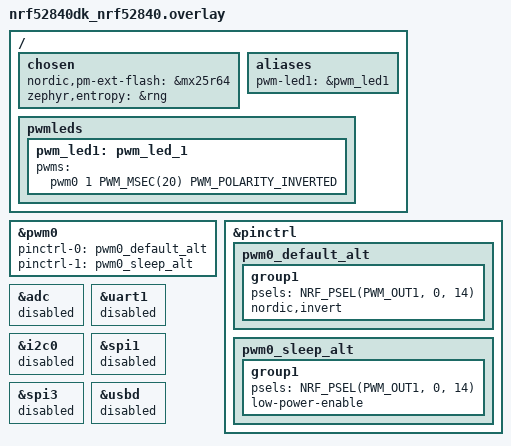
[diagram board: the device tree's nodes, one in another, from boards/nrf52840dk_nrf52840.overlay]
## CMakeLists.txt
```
#
# Copyright (c) 2021 Nordic Semiconductor ASA
#
# SPDX-License-Identifier: LicenseRef-Nordic-5-Clause
#

cmake_minimum_required(VERSION 3.20.0)

find_package(Zephyr HINTS $ENV{ZEPHYR_BASE})

project(matter-light-bulb)

# Enable GNU STD support.
include(${ZEPHYR_CONNECTEDHOMEIP_MODULE_DIR}/config/nrfconnect/app/enable-gnu-std.cmake)

# NORDIC SDK APP START

# Include all source files that are located in the Matter common directory.
include(${ZEPHYR_NRF_MODULE_DIR}/samples/matter/common/cmake/source_common.cmake)

# Include Data Model utils
include(${ZEPHYR_NRF_MODULE_DIR}/samples/matter/common/cmake/data_model.cmake)

target_include_directories(app PRIVATE
    src
    ${CONFIG_NCS_SAMPLE_MATTER_ZAP_FILES_PATH}
)

target_sources(app PRIVATE
    src/app_task.cpp
    src/main.cpp
    src/zcl_callbacks.cpp
)

ncs_configure_data_model(
    ZAP_FILE ${CMAKE_CURRENT_SOURCE_DIR}/${CONFIG_NCS_SAMPLE_MATTER_ZAP_FILES_PATH}/thread_platform.zap
)
# NORDIC SDK APP END
```

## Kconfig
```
#
# Copyright (c) 2022 Nordic Semiconductor
#
# SPDX-License-Identifier: LicenseRef-Nordic-5-Clause
#
mainmenu "Matter nRF Connect Platform"

# Sample configuration used for Thread networking
if OPENTHREAD

choice OPENTHREAD_NORDIC_LIBRARY_CONFIGURATION
	default OPENTHREAD_NORDIC_LIBRARY_MTD
endchoice

choice OPENTHREAD_DEVICE_TYPE
	default OPENTHREAD_MTD
endchoice

config CHIP_ENABLE_ICD_SUPPORT
	default y

config CHIP_ICD_LIT_SUPPORT
	default y

config CHIP_ICD_SIT_SLOW_POLL_LIMIT
	default 5000

config CHIP_ICD_REPORT_ON_ACTIVE_MODE
	default y

# Increase the supported event triggers due to the multiple alarm triggers
config NCS_SAMPLE_MATTER_TEST_EVENT_TRIGGERS_MAX
	default 12

# Reduce Thread TX output power to 0 dBm for SED device
config OPENTHREAD_DEFAULT_TX_POWER
	int
	default 0

endif # OPENTHREAD

source "${ZEPHYR_CONNECTEDHOMEIP_MODULE_DIR}/config/nrfconnect/chip-module/Kconfig.features"
source "${ZEPHYR_CONNECTEDHOMEIP_MODULE_DIR}/config/nrfconnect/chip-module/Kconfig.defaults"
source "${ZEPHYR_NRF_MODULE_DIR}/samples/matter/common/src/Kconfig"
source "Kconfig.zephyr"
```

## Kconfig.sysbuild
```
#
# Copyright (c) 2023 Nordic Semiconductor ASA
#
# SPDX-License-Identifier: LicenseRef-Nordic-5-Clause
#

config WIFI_NRF70
	default y if BOARD_NRF7002DK

#### Radio core selection
config NRF_DEFAULT_IPC_RADIO
	default y

# Enable IEEE802.15.4 serialization to network core
# This config automatically pulls in the `overlay-802154.conf` in the ipc_radio image
config NETCORE_IPC_RADIO_IEEE802154
	default y if SOC_SERIES_NRF53X && !WIFI_NRF70

# Enable Bluetooth serialization to network core
# This config automatically pulls in the `overlay-bt_hci_ipc.conf` in the ipc_radio image
config NETCORE_IPC_RADIO_BT_HCI_IPC
	default y if SOC_SERIES_NRF53X

#### Bootloader
choice BOOTLOADER
	default BOOTLOADER_MCUBOOT if !BOARD_NRF21540DK
endchoice

if BOOTLOADER_MCUBOOT

#### DFU multi-image support
config DFU_MULTI_IMAGE_PACKAGE_BUILD
	default y

config DFU_MULTI_IMAGE_PACKAGE_APP
	default y

config PM_EXTERNAL_FLASH_MCUBOOT_SECONDARY
	default y

#### DFU network core configuration
if SOC_SERIES_NRF53X

config MCUBOOT_UPDATEABLE_IMAGES
	default 2

choice MCUBOOT_MODE
	default MCUBOOT_MODE_OVERWRITE_ONLY
endchoice

choice BOOT_SIGNATURE_TYPE
	default BOOT_SIGNATURE_TYPE_RSA
endchoice

config SECURE_BOOT_NETCORE
	default y

config NETCORE_APP_UPDATE
	default y

config DFU_MULTI_IMAGE_PACKAGE_NET
	default y

endif # SOC_SERIES_NRF53X

if BOARD_NRF54L15DK

config PM_OVERRIDE_EXTERNAL_DRIVER_CHECK
	default y

endif # BOARD_NRF54L15DK

endif # BOOTLOADER_MCUBOOT

#### Enable generating factory data
config MATTER_FACTORY_DATA_GENERATE
	default y if !BOARD_NRF21540DK

source "share/sysbuild/Kconfig"
```

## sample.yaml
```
sample:
  description: Matter Platform
  name: Matter Platform
tests:
  sample.matter.platform.debug:
    sysbuild: true
    build_only: true
    extra_args:
      - platform_SNIPPET="diagnostic-logs;matter-debug"
    integration_platforms:
      - nrf52840dk/nrf52840
      - nrf5340dk/nrf5340/cpuapp
      - nrf54l15dk/nrf54l15/cpuapp
      - nrf54l15dk/nrf54l15/cpuapp/ns
    platform_allow:
      - nrf52840dk/nrf52840
      - nrf5340dk/nrf5340/cpuapp
      - nrf54l15dk/nrf54l15/cpuapp
      - nrf54l15dk/nrf54l15/cpuapp/ns
    tags:
      - sysbuild
      - ci_samples_matter
```

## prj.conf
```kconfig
#
# Copyright (c) 2022 Nordic Semiconductor ASA
#
# SPDX-License-Identifier: LicenseRef-Nordic-5-Clause
#

# Enable CHIP
CONFIG_CHIP=y
CONFIG_CHIP_PROJECT_CONFIG="src/chip_project_config.h"
# 32773 == 0x8005 (example lighting-app)
CONFIG_CHIP_DEVICE_PRODUCT_ID=32773
CONFIG_STD_CPP17=y

# Enable Matter pairing automatically on application start.
CONFIG_CHIP_ENABLE_PAIRING_AUTOSTART=y

# Enable Matter extended announcement and increase duration to 1 hour.
CONFIG_CHIP_BLE_EXT_ADVERTISING=y
CONFIG_CHIP_BLE_ADVERTISING_DURATION=60

# Add support for LEDs and buttons on Nordic development kits
CONFIG_DK_LIBRARY=y
CONFIG_PWM=y

# Bluetooth Low Energy configuration
CONFIG_BT_DEVICE_NAME="MatterPlatform"

# Other settings
CONFIG_THREAD_NAME=y
CONFIG_MPU_STACK_GUARD=y
CONFIG_RESET_ON_FATAL_ERROR=n
CONFIG_CHIP_LIB_SHELL=y
CONFIG_NCS_SAMPLE_MATTER_TEST_SHELL=y

# Reduce application size
CONFIG_USE_SEGGER_RTT=n

# Enable Factory Data feature
CONFIG_CHIP_FACTORY_DATA=y
CONFIG_CHIP_FACTORY_DATA_BUILD=y

CONFIG_CHIP_ENABLE_READ_CLIENT=y
```

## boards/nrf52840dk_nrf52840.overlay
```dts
/*
 * Copyright (c) 2021-2022 Nordic Semiconductor ASA
 *
 * SPDX-License-Identifier: LicenseRef-Nordic-5-Clause
 */

/ {
	chosen {
		nordic,pm-ext-flash = &mx25r64;
	};

	/*
	* In some default configurations within the nRF Connect SDK,
	* e.g. on nRF52840, the chosen zephyr,entropy node is &cryptocell.
	* This devicetree overlay ensures that default is overridden wherever it
	* is set, as this application uses the RNG node for entropy exclusively.
	*/

	chosen {
		zephyr,entropy = &rng;
	};

	/*
	* By default, PWM module is only configured for led0 (LED1 on the board).
	* The light bulb app, however, uses LED2 to show the state of the lighting,
	* including its brightness level.
	*/
	aliases {
		pwm-led1 = &pwm_led1;
	};

	pwmleds {
		pwm_led1: pwm_led_1 {
			pwms = <&pwm0 1 PWM_MSEC(20) PWM_POLARITY_INVERTED>;
		};
	};

};

&pwm0 {
	pinctrl-0 = <&pwm0_default_alt>;
	pinctrl-1 = <&pwm0_sleep_alt>;
	pinctrl-names = "default", "sleep";
};

&pinctrl {
	pwm0_default_alt: pwm0_default_alt {
		group1 {
			psels = <NRF_PSEL(PWM_OUT1, 0, 14)>;
			nordic,invert;
		};
	};

	pwm0_sleep_alt: pwm0_sleep_alt {
		group1 {
			psels = <NRF_PSEL(PWM_OUT1, 0, 14)>;
			low-power-enable;
		};
	};

};

/* Disable unused peripherals to reduce power consumption */
&adc {
	status = "disabled";
};
&uart1 {
	status = "disabled";
};
&i2c0 {
	status = "disabled";
};
&spi1 {
	status = "disabled";
};
&spi3 {
	status = "disabled";
};
&usbd {
	status = "disabled";
};
```

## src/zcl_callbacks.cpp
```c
/*
 * Copyright (c) 2021 Nordic Semiconductor ASA
 *
 * SPDX-License-Identifier: LicenseRef-Nordic-5-Clause
 */

#include <lib/support/logging/CHIPLogging.h>

#include "app_task.h"

#include <app-common/zap-generated/attributes/Accessors.h>
#include <app-common/zap-generated/ids/Attributes.h>
#include <app-common/zap-generated/ids/Clusters.h>
#include <app/ConcreteAttributePath.h>

using namespace ::chip;
using namespace ::chip::app::Clusters;
using namespace ::chip::app::Clusters::OnOff;

void MatterPostAttributeChangeCallback(const chip::app::ConcreteAttributePath &attributePath, uint8_t type,
				       uint16_t size, uint8_t *value)
{
	ClusterId clusterId = attributePath.mClusterId;
	AttributeId attributeId = attributePath.mAttributeId;

	if (clusterId == OnOff::Id && attributeId == OnOff::Attributes::OnOff::Id) {
		ChipLogProgress(Zcl, "Cluster OnOff: attribute OnOff set to %" PRIu8 "", *value);

#if defined(CONFIG_PWM)
		AppTask::Instance().GetPWMDevice().InitiateAction(*value ? Nrf::PWMDevice::ON_ACTION :
									   Nrf::PWMDevice::OFF_ACTION,
								  static_cast<int32_t>(LightingActor::Remote), value);
#else
		Nrf::GetBoard().GetLED(Nrf::DeviceLeds::LED2).Set(*value);
#endif

	} else if (clusterId == LevelControl::Id && attributeId == LevelControl::Attributes::CurrentLevel::Id) {
		ChipLogProgress(Zcl, "Cluster LevelControl: attribute CurrentLevel set to %" PRIu8 "", *value);
#if defined(CONFIG_PWM)
		if (AppTask::Instance().GetPWMDevice().IsTurnedOn()) {
			AppTask::Instance().GetPWMDevice().InitiateAction(
				Nrf::PWMDevice::LEVEL_ACTION, static_cast<int32_t>(LightingActor::Remote), value);
		} else {
			ChipLogDetail(Zcl, "LED is off. Try to use move-to-level-with-on-off instead of move-to-level");
		}
#endif

	}
}

/** @brief OnOff Cluster Init
 *
 * This function is called when a specific cluster is initialized. It gives the
 * application an opportunity to take care of cluster initialization procedures.
 * It is called exactly once for each endpoint where cluster is present.
 *
 * @param endpoint   Ver.: always
 *
 * TODO Issue #3841
 * emberAfOnOffClusterInitCallback happens before the stack initialize the cluster
 * attributes to the default value.
 * The logic here expects something similar to the deprecated Plugins callback
 * emberAfPluginOnOffClusterServerPostInitCallback.
 *
 */
void emberAfOnOffClusterInitCallback(EndpointId endpoint)
{
	Protocols::InteractionModel::Status status;
	bool storedValue;

	/* Read storedValue on/off value */
	status = Attributes::OnOff::Get(endpoint, &storedValue);
	if (status == Protocols::InteractionModel::Status::Success) {
		/* Set actual state to the cluster state that was last persisted */
#if defined(CONFIG_PWM)
		AppTask::Instance().InitPWMDDevice();

		AppTask::Instance().GetPWMDevice().InitiateAction(
			storedValue ? Nrf::PWMDevice::ON_ACTION : Nrf::PWMDevice::OFF_ACTION,
			static_cast<int32_t>(LightingActor::Remote), reinterpret_cast<uint8_t *>(&storedValue));
#else
		Nrf::GetBoard().GetLED(Nrf::DeviceLeds::LED2).Set(storedValue);
#endif
	}

	AppTask::Instance().UpdateClusterState();
}
```
